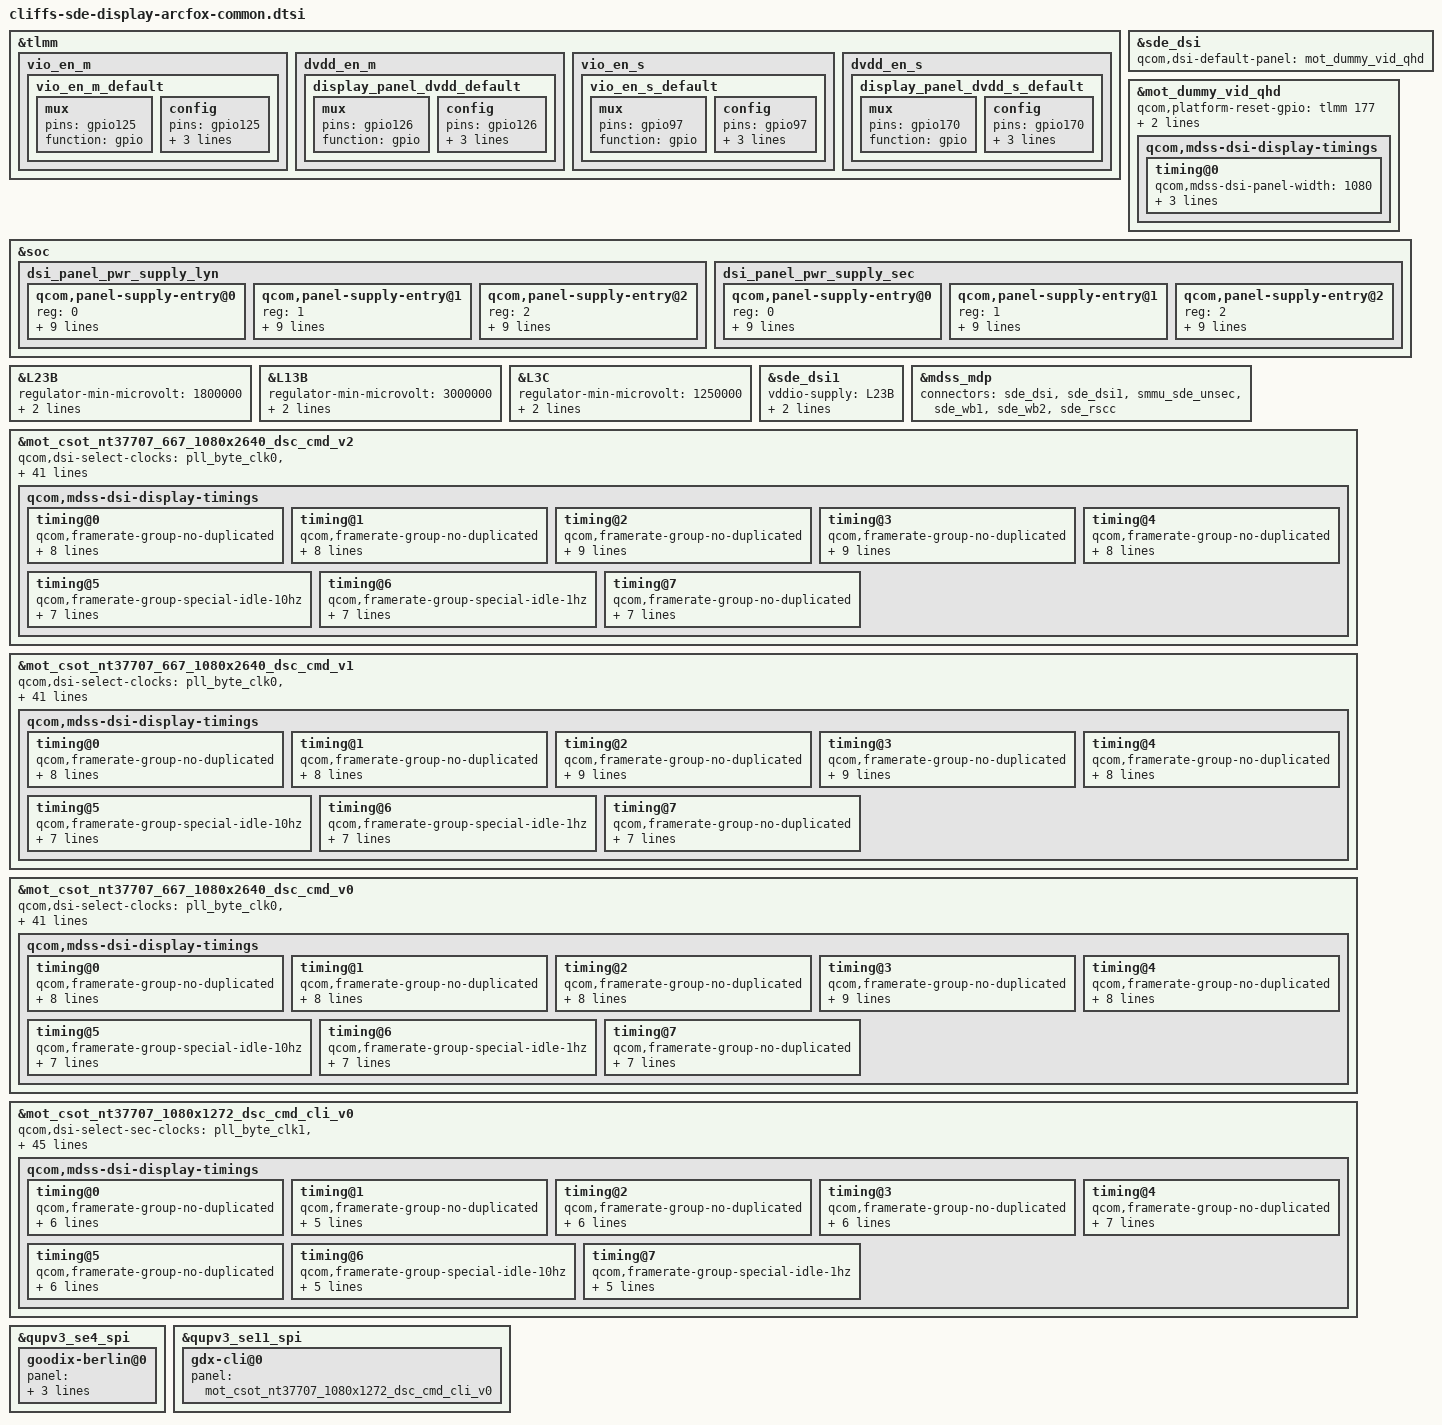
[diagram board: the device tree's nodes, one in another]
/* This is derivated from qcom cliffs-sde-display-mtp.dtsi */

#include "cliffs-sde-display.dtsi"
#include "dsi-panel-mot-dummy-qhd-video.dtsi"
#include "dsi-panel-mot-csot-nt37707-667-1080x2640-dsc-cmd-common_v0.dtsi"
#include "dsi-panel-mot-csot-nt37707-1080x1272-dsc-cmd-common-cli_v0.dtsi"
#include "dsi-panel-mot-csot-nt37707-667-1080x2640-dsc-cmd-common_v1.dtsi"
#include "dsi-panel-mot-csot-nt37707-667-1080x2640-dsc-cmd-common_v2.dtsi"

&tlmm {
	vio_en_m {
		vio_en_m_default: vio_en_m_default {//vio enable 1.8V
			mux {
				pins = "gpio125";
				function = "gpio";
			};

			config {
				pins = "gpio125";
				drive-strength = <2>;   /* 2 mA */
				bias-disable = <0>;   /* no pull */
				output-high;
			};
		};
	};
	dvdd_en_m {
		display_panel_dvdd_default: display_panel_dvdd_default { //dvdd 1.23V
			mux {
				pins = "gpio126";
				function = "gpio";
			};

			config {
				pins = "gpio126";
				drive-strength = <2>;   /* 2 mA */
				bias-disable = <0>;   /* no pull */
				output-enable;
			};
		};
	};
	vio_en_s {
		vio_en_s_default: vio_en_s_default {
			mux {
				pins = "gpio97";
				function = "gpio";
			};

			config {
				pins = "gpio97";
				drive-strength = <2>;   /* 2 mA */
				bias-disable = <0>;   /* no pull */
				output-high;
			};
		};
	};
	dvdd_en_s {
		display_panel_dvdd_s_default: display_panel_dvdd_s_default {
			mux {
				pins = "gpio170";
				function = "gpio";
			};

			config {
				pins = "gpio170";
				drive-strength = <2>;   /* 2 mA */
				bias-disable = <0>;   /* no pull */
				output-enable;
			};
		};
	};
};

&sde_dsi {
	qcom,dsi-default-panel = <&mot_dummy_vid_qhd>;
};

&mot_dummy_vid_qhd {
       qcom,mdss-dsi-display-timings {
                timing@0{
                       qcom,mdss-dsi-panel-width = <1080>;
                       qcom,mdss-dsi-panel-height = <2400>;
               };
       };
};
&soc {
	dsi_panel_pwr_supply_lyn: dsi_panel_pwr_supply_lyn {
		#address-cells = <1>;
		#size-cells = <0>;

	qcom,panel-supply-entry@0 {
		reg = <0>;
		qcom,supply-name = "vddio";
		qcom,supply-min-voltage = <1800000>;
		qcom,supply-max-voltage = <1800000>;
		qcom,supply-enable-load = <300000>;
		qcom,supply-disable-load = <100>;
		qcom,supply-pre-on-sleep = <1>;
		qcom,supply-post-on-sleep = <1>;
		qcom,supply-pre-off-sleep = <3>;
		qcom,supply-post-off-sleep = <0>;
        };
	qcom,panel-supply-entry@1 {
		reg = <1>;
		qcom,supply-name = "vdd";
		qcom,supply-min-voltage = <1200000>;
		qcom,supply-max-voltage = <1250000>;
		qcom,supply-enable-load = <300000>;
		qcom,supply-disable-load = <100>;
		qcom,supply-pre-on-sleep = <1>;
		qcom,supply-post-on-sleep = <1>;
		qcom,supply-pre-off-sleep = <3>;
		qcom,supply-post-off-sleep = <0>;
        };

        qcom,panel-supply-entry@2 {
		reg = <2>;
		qcom,supply-name = "vci";
		qcom,supply-min-voltage = <3000000>;
		qcom,supply-max-voltage = <3000000>;
		qcom,supply-enable-load = <300000>;
		qcom,supply-disable-load = <0>;
		qcom,supply-pre-on-sleep = <1>;
		qcom,supply-post-on-sleep = <0>;
		qcom,supply-pre-off-sleep = <2>;
		qcom,supply-post-off-sleep = <0>;
        };
	};
	dsi_panel_pwr_supply_sec: dsi_panel_pwr_supply_sec {
		#address-cells = <1>;
		#size-cells = <0>;

	qcom,panel-supply-entry@0 {
		reg = <0>;
		qcom,supply-name = "vddio";
		qcom,supply-min-voltage = <1800000>;
		qcom,supply-max-voltage = <1800000>;
		qcom,supply-enable-load = <300000>;
		qcom,supply-disable-load = <100>;
		qcom,supply-pre-on-sleep = <1>;
		qcom,supply-post-on-sleep = <1>;
		qcom,supply-pre-off-sleep = <3>;
		qcom,supply-post-off-sleep = <0>;
        };
	qcom,panel-supply-entry@1 {
		reg = <1>;
		qcom,supply-name = "vdd";
		qcom,supply-min-voltage = <1250000>;
		qcom,supply-max-voltage = <1250000>;
		qcom,supply-enable-load = <300000>;
		qcom,supply-disable-load = <100>;
		qcom,supply-pre-on-sleep = <1>;
		qcom,supply-post-on-sleep = <1>;
		qcom,supply-pre-off-sleep = <3>;
		qcom,supply-post-off-sleep = <0>;
        };

        qcom,panel-supply-entry@2 {
		reg = <2>;
		qcom,supply-name = "vci";
		qcom,supply-min-voltage = <3000000>;
		qcom,supply-max-voltage = <3000000>;
		qcom,supply-enable-load = <300000>;
		qcom,supply-disable-load = <0>;
		qcom,supply-pre-on-sleep = <1>;
		qcom,supply-post-on-sleep = <0>;
		qcom,supply-pre-off-sleep = <2>;
		qcom,supply-post-off-sleep = <0>;
        };
	};
};
&L23B {
       regulator-min-microvolt = <1800000>;
       regulator-max-microvolt = <1800000>;
       qcom,init-voltage = <1800000>;
};
&L13B {
       regulator-min-microvolt = <3000000>;
       regulator-max-microvolt = <3000000>;
       qcom,init-voltage = <3000000>;
};

&L3C {
       regulator-min-microvolt = <1250000>;
       regulator-max-microvolt = <1250000>;
       qcom,init-voltage = <1250000>;
};

&sde_dsi1 {
	vddio-supply = <&L23B>;
	vdd-supply = <&L3C>;
	vci-supply = <&L13B>;
};


&mdss_mdp {
	connectors = <&sde_dsi &sde_dsi1 &smmu_sde_unsec &sde_wb1 &sde_wb2 &sde_rscc>;
};

&mot_csot_nt37707_667_1080x2640_dsc_cmd_v2 {
	qcom,dsi-select-clocks = "pll_byte_clk0", "pll_dsi_clk0";
	qcom,panel-supply-entries = <&dsi_panel_pwr_supply_lyn>;
	qcom,mdss-dsi-no-panel-on-read-support;
	qcom,mdss-dsi-bl-pmic-control-type = "bl_ctrl_dcs";
	qcom,mdss-dsi-bl-min-level = <420>;
	qcom,mdss-dsi-bl-max-level = <16380>;
	qcom,mdss-dsi-bl-default-level = <10230>;
	qcom,mdss-brightness-max-level = <16380>;
	qcom,platform-reset-gpio = <&tlmm 177 0>;
	qcom,platform-vio-enable-gpio = <&tlmm 125 0>;
	qcom,platform-vdd-enable-gpio = <&tlmm 126 0>;
	qcom,bl-dsc-cmd-state = "dsi_hs_mode";
	qcom,mdss-dsi-bl-inverted-dbv;
	qcom,mdss-dsi-bl-is-exponent;


	qcom,mdss-dsi-panel-status-check-mode = "reg_read";
	qcom,mdss-dsi-panel-status-command = [06 01 00 01 00 00 01 0a];
	qcom,mdss-dsi-panel-status-command-state = "dsi_lp_mode";
	qcom,mdss-dsi-panel-status-value = <0x9c>;
	qcom,mdss-dsi-panel-status-read-length = <1>;
	qcom,esd-check-enabled;
	qcom,cellid-read-enabled;
	qcom,mdss-dsi-panel-cellid-read-length = <36>;
	qcom,mdss-dsi-panel-cellid-offset = <13>;
	qcom,mdss-dsi-panel-cellid-command = [
		06 01 00 01 00 00 01 AC];

	qcom,mdss-dsi-panel-hdr-enabled;
	qcom,mdss-dsi-panel-hdr-color-primaries = <15600 16450 34000
	        16000 13250 34500 7500 3000>;
	qcom,mdss-dsi-panel-peak-brightness = <15000000>;
	qcom,mdss-dsi-panel-blackness-level = <1>;

	qcom,apl-enabled;
	qcom,mdss-dsi-panel-APL-THRESHOLD-BL = <14258>;
	qcom,mdss-dsi-panel-apl-on-command = [
		39 00 00 00 00 00 03 5F 00 01];
	qcom,mdss-dsi-panel-apl-off-command = [
		39 00 00 00 00 00 03 5F 00 00];

	//qcom,ulps-enabled;
	qcom,mdss-dsi-display-timings {
		timing@0 { //120
			qcom,framerate-group-no-duplicated;
			qcom,framerate-group-120hz-based;
			qcom,partial-update-enabled = "single_roi";
			qcom,panel-roi-alignment = <1080 120 1080 120 1080 120>;
			//qcom,mdss-dsi-panel-clockrate = <800000000>;
			qcom,display-topology = <1 1 1>;
			qcom,default-topology-index = <0>;
			qcom,mdss-dsi-panel-phy-timings = [00 1B 07 06 16 15 07
							07 07 02 04 00 17 0C];
		};
		timing@1 { //90
			qcom,framerate-group-no-duplicated;
			qcom,framerate-group-90hz-based;
			qcom,partial-update-enabled = "single_roi";
			qcom,panel-roi-alignment = <1080 120 1080 120 1080 120>;
			//qcom,mdss-dsi-panel-clockrate = <600000000>;
			qcom,display-topology = <1 1 1>;
			qcom,default-topology-index = <0>;
			qcom,mdss-dsi-panel-phy-timings = [00 16 05 05 14 1F 06
							05 06 02 04 00 13 0A];
		};
		timing@2 { //60
			qcom,framerate-group-no-duplicated;
			qcom,framerate-group-120hz-based;
			qcom,partial-update-enabled = "single_roi";
			qcom,panel-roi-alignment = <1080 120 1080 120 1080 120>;
			qcom,mdss-dsi-panel-clockrate = <500000000>;
			qcom,display-topology = <1 1 1>;
			qcom,default-topology-index = <0>;
			qcom,mdss-dsi-panel-phy-timings = [00 1B 07 06 16 21 07
							07 07 02 04 00 17 0C];
		};
		timing@3 { //30
			qcom,framerate-group-no-duplicated;
			qcom,framerate-group-120hz-based;
			qcom,framerate-group-90hz-based;
			qcom,partial-update-enabled = "single_roi";
			qcom,panel-roi-alignment = <1080 120 1080 120 1080 120>;
			//qcom,mdss-dsi-panel-clockrate = <800000000>;
			qcom,display-topology = <1 1 1>;
			qcom,default-topology-index = <0>;
			qcom,mdss-dsi-panel-phy-timings = [00 1B 07 06 16 21 07
							07 07 02 04 00 17 0C];
		};
		timing@4 { //24
			qcom,framerate-group-no-duplicated;
			qcom,framerate-group-120hz-based;
			qcom,partial-update-enabled = "single_roi";
			qcom,panel-roi-alignment = <1080 120 1080 120 1080 120>;
			//qcom,mdss-dsi-panel-clockrate = <800000000>;
			qcom,display-topology = <1 1 1>;
			qcom,default-topology-index = <0>;
			qcom,mdss-dsi-panel-phy-timings = [00 1B 07 06 16 15 07
							07 07 02 04 00 17 0C];
		};
		timing@5 { //10 independent
			qcom,framerate-group-special-idle-10hz;
			qcom,partial-update-enabled = "single_roi";
			qcom,panel-roi-alignment = <1080 120 1080 120 1080 120>;
			//qcom,mdss-dsi-panel-clockrate = <809000000>;
			qcom,display-topology = <1 1 1>;
			qcom,default-topology-index = <0>;
			qcom,mdss-dsi-panel-phy-timings = [00 1B 07 07 17 15 07
							07 08 02 04 00 18 0C];
		};
		timing@6 { //1 independent
			qcom,framerate-group-special-idle-1hz;
			qcom,partial-update-enabled = "single_roi";
			qcom,panel-roi-alignment = <1080 120 1080 120 1080 120>;
			//qcom,mdss-dsi-panel-clockrate = <809000000>;
			qcom,display-topology = <1 1 1>;
			qcom,default-topology-index = <0>;
			qcom,mdss-dsi-panel-phy-timings = [00 1B 07 07 17 15 07
							07 08 02 04 00 18 0C];
		};
		timing@7 { //165
			qcom,framerate-group-no-duplicated;
			qcom,partial-update-enabled = "single_roi";
			qcom,panel-roi-alignment = <1080 120 1080 120 1080 120>;
			//qcom,mdss-dsi-panel-clockrate = <1100000000>;
			qcom,display-topology = <1 1 1>;
			qcom,default-topology-index = <0>;
			qcom,mdss-dsi-panel-phy-timings = [00 24 0A 0A 1A 19 09
							0A 09 02 04 00 1E 0F];
		};
	};
};

&mot_csot_nt37707_667_1080x2640_dsc_cmd_v1 {
	qcom,dsi-select-clocks = "pll_byte_clk0", "pll_dsi_clk0";
	qcom,panel-supply-entries = <&dsi_panel_pwr_supply_lyn>;
	qcom,mdss-dsi-no-panel-on-read-support;
	qcom,mdss-dsi-bl-pmic-control-type = "bl_ctrl_dcs";
	qcom,mdss-dsi-bl-min-level = <420>;
	qcom,mdss-dsi-bl-max-level = <16380>;
	qcom,mdss-dsi-bl-default-level = <10230>;
	qcom,mdss-brightness-max-level = <16380>;
	qcom,platform-reset-gpio = <&tlmm 177 0>;
	qcom,platform-vio-enable-gpio = <&tlmm 125 0>;
	qcom,platform-vdd-enable-gpio = <&tlmm 126 0>;
	qcom,bl-dsc-cmd-state = "dsi_hs_mode";
	qcom,mdss-dsi-bl-inverted-dbv;
	qcom,mdss-dsi-bl-is-exponent;


	qcom,mdss-dsi-panel-status-check-mode = "reg_read";
	qcom,mdss-dsi-panel-status-command = [06 01 00 01 00 00 01 0a];
	qcom,mdss-dsi-panel-status-command-state = "dsi_lp_mode";
	qcom,mdss-dsi-panel-status-value = <0x9c>;
	qcom,mdss-dsi-panel-status-read-length = <1>;
	qcom,esd-check-enabled;
	qcom,cellid-read-enabled;
	qcom,mdss-dsi-panel-cellid-read-length = <36>;
	qcom,mdss-dsi-panel-cellid-offset = <13>;
	qcom,mdss-dsi-panel-cellid-command = [
		06 01 00 01 00 00 01 AC];

	qcom,mdss-dsi-panel-hdr-enabled;
	qcom,mdss-dsi-panel-hdr-color-primaries = <15600 16450 34000
	        16000 13250 34500 7500 3000>;
	qcom,mdss-dsi-panel-peak-brightness = <15000000>;
	qcom,mdss-dsi-panel-blackness-level = <1>;

	qcom,apl-enabled;
	qcom,mdss-dsi-panel-APL-THRESHOLD-BL = <14258>;
	qcom,mdss-dsi-panel-apl-on-command = [
		39 00 00 00 00 00 03 5F 00 01];
	qcom,mdss-dsi-panel-apl-off-command = [
		39 00 00 00 00 00 03 5F 00 00];

	//qcom,ulps-enabled;
	qcom,mdss-dsi-display-timings {
		timing@0 { //120
			qcom,framerate-group-no-duplicated;
			qcom,framerate-group-120hz-based;
			qcom,partial-update-enabled = "single_roi";
			qcom,panel-roi-alignment = <1080 120 1080 120 1080 120>;
			//qcom,mdss-dsi-panel-clockrate = <800000000>;
			qcom,display-topology = <1 1 1>;
			qcom,default-topology-index = <0>;
			qcom,mdss-dsi-panel-phy-timings = [00 1B 07 06 16 15 07
							07 07 02 04 00 17 0C];
		};
		timing@1 { //90
			qcom,framerate-group-no-duplicated;
			qcom,framerate-group-90hz-based;
			qcom,partial-update-enabled = "single_roi";
			qcom,panel-roi-alignment = <1080 120 1080 120 1080 120>;
			//qcom,mdss-dsi-panel-clockrate = <600000000>;
			qcom,display-topology = <1 1 1>;
			qcom,default-topology-index = <0>;
			qcom,mdss-dsi-panel-phy-timings = [00 16 05 05 14 1F 06
							05 06 02 04 00 13 0A];
		};
		timing@2 { //60
			qcom,framerate-group-no-duplicated;
			qcom,framerate-group-120hz-based;
			qcom,partial-update-enabled = "single_roi";
			qcom,panel-roi-alignment = <1080 120 1080 120 1080 120>;
			qcom,mdss-dsi-panel-clockrate = <500000000>;
			qcom,display-topology = <1 1 1>;
			qcom,default-topology-index = <0>;
			qcom,mdss-dsi-panel-phy-timings = [00 1B 07 06 16 21 07
							07 07 02 04 00 17 0C];
		};
		timing@3 { //30
			qcom,framerate-group-no-duplicated;
			qcom,framerate-group-120hz-based;
			qcom,framerate-group-90hz-based;
			qcom,partial-update-enabled = "single_roi";
			qcom,panel-roi-alignment = <1080 120 1080 120 1080 120>;
			//qcom,mdss-dsi-panel-clockrate = <800000000>;
			qcom,display-topology = <1 1 1>;
			qcom,default-topology-index = <0>;
			qcom,mdss-dsi-panel-phy-timings = [00 1B 07 06 16 21 07
							07 07 02 04 00 17 0C];
		};
		timing@4 { //24
			qcom,framerate-group-no-duplicated;
			qcom,framerate-group-120hz-based;
			qcom,partial-update-enabled = "single_roi";
			qcom,panel-roi-alignment = <1080 120 1080 120 1080 120>;
			//qcom,mdss-dsi-panel-clockrate = <800000000>;
			qcom,display-topology = <1 1 1>;
			qcom,default-topology-index = <0>;
			qcom,mdss-dsi-panel-phy-timings = [00 1B 07 06 16 15 07
							07 07 02 04 00 17 0C];
		};
		timing@5 { //10 independent
			qcom,framerate-group-special-idle-10hz;
			qcom,partial-update-enabled = "single_roi";
			qcom,panel-roi-alignment = <1080 120 1080 120 1080 120>;
			//qcom,mdss-dsi-panel-clockrate = <809000000>;
			qcom,display-topology = <1 1 1>;
			qcom,default-topology-index = <0>;
			qcom,mdss-dsi-panel-phy-timings = [00 1B 07 07 17 15 07
							07 08 02 04 00 18 0C];
		};
		timing@6 { //1 independent
			qcom,framerate-group-special-idle-1hz;
			qcom,partial-update-enabled = "single_roi";
			qcom,panel-roi-alignment = <1080 120 1080 120 1080 120>;
			//qcom,mdss-dsi-panel-clockrate = <809000000>;
			qcom,display-topology = <1 1 1>;
			qcom,default-topology-index = <0>;
			qcom,mdss-dsi-panel-phy-timings = [00 1B 07 07 17 15 07
							07 08 02 04 00 18 0C];
		};
		timing@7 { //165
			qcom,framerate-group-no-duplicated;
			qcom,partial-update-enabled = "single_roi";
			qcom,panel-roi-alignment = <1080 120 1080 120 1080 120>;
			//qcom,mdss-dsi-panel-clockrate = <1100000000>;
			qcom,display-topology = <1 1 1>;
			qcom,default-topology-index = <0>;
			qcom,mdss-dsi-panel-phy-timings = [00 24 0A 0A 1A 19 09
							0A 09 02 04 00 1E 0F];
		};
	};
};

&mot_csot_nt37707_667_1080x2640_dsc_cmd_v0 {
	qcom,dsi-select-clocks = "pll_byte_clk0", "pll_dsi_clk0";
	qcom,panel-supply-entries = <&dsi_panel_pwr_supply_lyn>;
	qcom,mdss-dsi-no-panel-on-read-support;
	qcom,mdss-dsi-bl-pmic-control-type = "bl_ctrl_dcs";
	qcom,mdss-dsi-bl-min-level = <420>;
	qcom,mdss-dsi-bl-max-level = <16380>;
	qcom,mdss-dsi-bl-default-level = <10230>;
	qcom,mdss-brightness-max-level = <16380>;
	qcom,platform-reset-gpio = <&tlmm 177 0>;
	qcom,platform-vio-enable-gpio = <&tlmm 125 0>;
	qcom,platform-vdd-enable-gpio = <&tlmm 126 0>;
	qcom,bl-dsc-cmd-state = "dsi_hs_mode";
	qcom,mdss-dsi-bl-inverted-dbv;
	qcom,mdss-dsi-bl-is-exponent;


	qcom,mdss-dsi-panel-status-check-mode = "reg_read";
	qcom,mdss-dsi-panel-status-command = [06 01 00 01 00 00 01 0a];
	qcom,mdss-dsi-panel-status-command-state = "dsi_lp_mode";
	qcom,mdss-dsi-panel-status-value = <0x9c>;
	qcom,mdss-dsi-panel-status-read-length = <1>;
	qcom,esd-check-enabled;
	qcom,cellid-read-enabled;
	qcom,mdss-dsi-panel-cellid-read-length = <36>;
	qcom,mdss-dsi-panel-cellid-offset = <13>;
	qcom,mdss-dsi-panel-cellid-command = [
		06 01 00 01 00 00 01 AC];

	qcom,mdss-dsi-panel-hdr-enabled;
	qcom,mdss-dsi-panel-hdr-color-primaries = <15600 16450 34000
	        16000 13250 34500 7500 3000>;
	qcom,mdss-dsi-panel-peak-brightness = <15000000>;
	qcom,mdss-dsi-panel-blackness-level = <1>;

	qcom,apl-enabled;
	qcom,mdss-dsi-panel-APL-THRESHOLD-BL = <14258>;
	qcom,mdss-dsi-panel-apl-on-command = [
		39 00 00 00 00 00 03 5F 00 01];
	qcom,mdss-dsi-panel-apl-off-command = [
		39 00 00 00 00 00 03 5F 00 00];

	//qcom,ulps-enabled;
	qcom,mdss-dsi-display-timings {
		timing@0 { //120
			qcom,framerate-group-no-duplicated;
			qcom,framerate-group-120hz-based;
			qcom,partial-update-enabled = "single_roi";
			qcom,panel-roi-alignment = <1080 120 1080 120 1080 120>;
			//qcom,mdss-dsi-panel-clockrate = <777000000>;
			qcom,display-topology = <1 1 1>;
			qcom,default-topology-index = <0>;
			qcom,mdss-dsi-panel-phy-timings = [00 1B 07 06 16 21 07
							07 07 02 04 00 17 0C];
		};
		timing@1 { //90
			qcom,framerate-group-no-duplicated;
			qcom,framerate-group-90hz-based;
			qcom,partial-update-enabled = "single_roi";
			qcom,panel-roi-alignment = <1080 120 1080 120 1080 120>;
			//qcom,mdss-dsi-panel-clockrate = <880000000>;
			qcom,display-topology = <1 1 1>;
			qcom,default-topology-index = <0>;
			qcom,mdss-dsi-panel-phy-timings = [00 1B 07 06 16 21 07
							07 07 02 04 00 17 0C];
		};
		timing@2 { //60
			qcom,framerate-group-no-duplicated;
			qcom,framerate-group-120hz-based;
			qcom,partial-update-enabled = "single_roi";
			qcom,panel-roi-alignment = <1080 120 1080 120 1080 120>;
			//qcom,mdss-dsi-panel-clockrate = <880000000>;
			qcom,display-topology = <1 1 1>;
			qcom,default-topology-index = <0>;
			qcom,mdss-dsi-panel-phy-timings = [00 1B 07 06 16 21 07
							07 07 02 04 00 17 0C];
		};
		timing@3 { //30
			qcom,framerate-group-no-duplicated;
			qcom,framerate-group-120hz-based;
			qcom,framerate-group-90hz-based;
			qcom,partial-update-enabled = "single_roi";
			qcom,panel-roi-alignment = <1080 120 1080 120 1080 120>;
			//qcom,mdss-dsi-panel-clockrate = <880000000>;
			qcom,display-topology = <1 1 1>;
			qcom,default-topology-index = <0>;
			qcom,mdss-dsi-panel-phy-timings = [00 1B 07 06 16 21 07
							07 07 02 04 00 17 0C];
		};
		timing@4 { //24
			qcom,framerate-group-no-duplicated;
			qcom,framerate-group-120hz-based;
			qcom,partial-update-enabled = "single_roi";
			qcom,panel-roi-alignment = <1080 120 1080 120 1080 120>;
			//qcom,mdss-dsi-panel-clockrate = <880000000>;
			qcom,display-topology = <1 1 1>;
			qcom,default-topology-index = <0>;
			qcom,mdss-dsi-panel-phy-timings = [00 1B 07 06 16 21 07
							07 07 02 04 00 17 0C];
		};
		timing@5 { //10 independent
			qcom,framerate-group-special-idle-10hz;
			qcom,partial-update-enabled = "single_roi";
			qcom,panel-roi-alignment = <1080 120 1080 120 1080 120>;
			//qcom,mdss-dsi-panel-clockrate = <880000000>;
			qcom,display-topology = <1 1 1>;
			qcom,default-topology-index = <0>;
			qcom,mdss-dsi-panel-phy-timings = [00 1B 07 06 16 21 07
							07 07 02 04 00 17 0C];
		};
		timing@6 { //1 independent
			qcom,framerate-group-special-idle-1hz;
			qcom,partial-update-enabled = "single_roi";
			qcom,panel-roi-alignment = <1080 120 1080 120 1080 120>;
			//qcom,mdss-dsi-panel-clockrate = <880000000>;
			qcom,display-topology = <1 1 1>;
			qcom,default-topology-index = <0>;
			qcom,mdss-dsi-panel-phy-timings = [00 1B 07 06 16 21 07
							07 07 02 04 00 17 0C];
		};
		timing@7 { //165
			qcom,framerate-group-no-duplicated;
			qcom,partial-update-enabled = "single_roi";
			qcom,panel-roi-alignment = <1080 120 1080 120 1080 120>;
			//qcom,mdss-dsi-panel-clockrate = <880000000>;
			qcom,display-topology = <1 1 1>;
			qcom,default-topology-index = <0>;
			qcom,mdss-dsi-panel-phy-timings = [00 24 0A 0A 1A 25 09
							0A 09 02 04 00 1E 0F];
		};
	};
};

&mot_csot_nt37707_1080x1272_dsc_cmd_cli_v0 {
	qcom,dsi-select-sec-clocks = "pll_byte_clk1", "pll_dsi_clk1";

	qcom,panel-supply-entries = <&dsi_panel_pwr_supply_lyn>;
	qcom,panel-sec-supply-entries = <&dsi_panel_pwr_supply_sec>;
	qcom,mdss-dsi-bl-pmic-control-type = "bl_ctrl_dcs";
	qcom,mdss-dsi-sec-bl-pmic-control-type = "bl_ctrl_dcs";
	qcom,mdss-dsi-bl-min-level = <420>;
	qcom,mdss-dsi-bl-max-level = <16380>;
	qcom,mdss-dsi-bl-default-level = <10230>;
	qcom,mdss-brightness-max-level = <16380>;
	qcom,platform-sec-reset-gpio = <&tlmm 141 0>;
	qcom,platform-sec-vio-enable-gpio = <&tlmm 97 0>;
	qcom,platform-sec-vdd-enable-gpio = <&tlmm 170 0>;
	qcom,mdss-dsi-panel-orientation = "180";
	qcom,mdss-dsi-panel-status-check-mode = "reg_read";
	qcom,mdss-dsi-panel-status-command = [06 01 00 01 00 00 01 0a];
	qcom,mdss-dsi-panel-status-command-state = "dsi_lp_mode";
	qcom,mdss-dsi-panel-status-value = <0x9c>;
	qcom,mdss-dsi-panel-status-read-length = <1>;
	qcom,esd-check-enabled;
	qcom,mdss-dsi-bl-inverted-dbv;
	qcom,mdss-dsi-bl-is-exponent;

	qcom,mdss-dsi-no-panel-on-read-support;
	qcom,cellid-read-enabled;
	qcom,mdss-dsi-panel-cellid-read-length = <36>;
	qcom,mdss-dsi-panel-cellid-offset = <13>;
	qcom,mdss-dsi-panel-cellid-command = [
		06 01 00 01 00 00 01 AC];

	qcom,mdss-dsi-panel-hdr-enabled;
	qcom,mdss-dsi-panel-hdr-color-primaries = <15600 16450 34000
	        16000 13250 34500 7500 3000>;
	qcom,mdss-dsi-panel-peak-brightness = <15000000>;
	qcom,mdss-dsi-panel-blackness-level = <1>;

	qcom,apl-enabled;
	qcom,mdss-dsi-panel-APL-THRESHOLD-BL = <16200>;
	qcom,mdss-dsi-panel-apl-on-command = [
		39 00 00 00 00 00 03 5F 00 01];
	qcom,mdss-dsi-panel-apl-off-command = [
		39 00 00 00 00 00 03 5F 00 00];

	qcom,mdss-dsi-display-timings {
		timing@0{//120hz
			qcom,framerate-group-no-duplicated;
			qcom,framerate-group-120hz-based;
		        qcom,mdss-dsi-panel-clockrate = <667500000>;
			qcom,display-topology = <1 1 1>;
			qcom,default-topology-index = <0>;
			qcom,mdss-dsi-panel-phy-timings = [00 10 04 04 12 11 04
							04 03 02 04 00 0E 09];
		};
		timing@1{//165hz
			qcom,framerate-group-no-duplicated;
			qcom,mdss-dsi-panel-clockrate = <667500000>;
			qcom,display-topology = <1 1 1>;
			qcom,default-topology-index = <0>;
			qcom,mdss-dsi-panel-phy-timings = [00 15 05 05 14 13 05
							05 06 02 04 00 13 0A];
		};
		timing@2{//90hz
			qcom,framerate-group-no-duplicated;
			qcom,framerate-group-90hz-based;
			qcom,mdss-dsi-panel-clockrate = <667500000>;
			qcom,display-topology = <1 1 1>;
			qcom,default-topology-index = <0>;
			qcom,mdss-dsi-panel-phy-timings = [00 10 04 04 12 11 04
							04 03 02 04 00 0E 09];
		};
		timing@3{//60hz
			qcom,framerate-group-no-duplicated;
			qcom,framerate-group-120hz-based;
			qcom,mdss-dsi-panel-clockrate = <667500000>;
			qcom,display-topology = <1 1 1>;
			qcom,default-topology-index = <0>;
			qcom,mdss-dsi-panel-phy-timings = [00 10 04 04 12 11 04
							04 03 02 04 00 0E 09];
		};
		timing@4{//30hz
			qcom,framerate-group-no-duplicated;
			qcom,framerate-group-120hz-based;
			qcom,framerate-group-90hz-based;
			qcom,mdss-dsi-panel-clockrate = <667500000>;
			qcom,display-topology = <1 1 1>;
			qcom,default-topology-index = <0>;
			qcom,mdss-dsi-panel-phy-timings = [00 10 04 04 12 11 04
							04 03 02 04 00 0E 09];
		};
		timing@5{//24hz
			qcom,framerate-group-no-duplicated;
			qcom,framerate-group-120hz-based;
			qcom,mdss-dsi-panel-clockrate = <667500000>;
			qcom,display-topology = <1 1 1>;
			qcom,default-topology-index = <0>;
			qcom,mdss-dsi-panel-phy-timings = [00 10 04 04 12 11 04
							04 03 02 04 00 0E 09];
		};
		timing@6{//10hz
			qcom,framerate-group-special-idle-10hz;
			qcom,mdss-dsi-panel-clockrate = <667500000>;
			qcom,display-topology = <1 1 1>;
			qcom,default-topology-index = <0>;
			qcom,mdss-dsi-panel-phy-timings = [00 10 04 04 12 11 04
							04 03 02 04 00 0E 09];
		};
		timing@7{//1hz
			qcom,framerate-group-special-idle-1hz;
			qcom,mdss-dsi-panel-clockrate = <667500000>;
			qcom,display-topology = <1 1 1>;
			qcom,default-topology-index = <0>;
			qcom,mdss-dsi-panel-phy-timings = [00 10 04 04 12 11 04
							04 03 02 04 00 0E 09];
		};
	};
};

&mot_dummy_vid_qhd {
	qcom,platform-reset-gpio = <&tlmm 177 0>;

	qcom,dsi-select-clocks = "pll_byte_clk0", "pll_dsi_clk0";
	qcom,mdss-dsi-display-timings {
		timing@0 {
			qcom,display-topology = <1 0 1>;
			qcom,default-topology-index = <0>;
		};
	};
};

&qupv3_se4_spi {
	goodix-berlin@0 {
		panel = <&mot_csot_nt37707_667_1080x2640_dsc_cmd_v0
			&mot_csot_nt37707_667_1080x2640_dsc_cmd_v1
			&mot_csot_nt37707_667_1080x2640_dsc_cmd_v2>;
	};
};

&qupv3_se11_spi {
	gdx-cli@0 {
		panel = <&mot_csot_nt37707_1080x1272_dsc_cmd_cli_v0>;
	};
};
